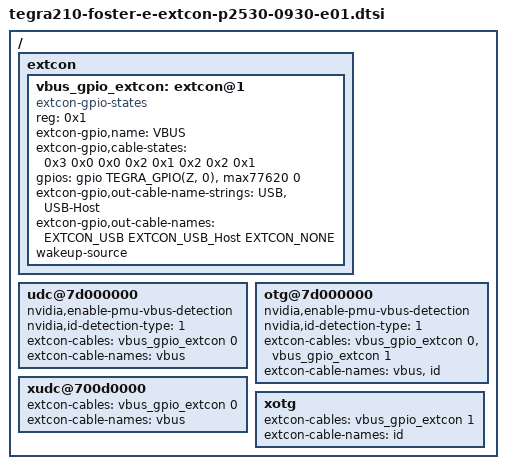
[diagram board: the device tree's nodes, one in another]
/*
 * Copyright (c) 2014-2016, NVIDIA CORPORATION.  All rights reserved.
 *
 * This program is free software; you can redistribute it and/or modify it
 * under the terms and conditions of the GNU General Public License,
 * version 2, as published by the Free Software Foundation.
 *
 * This program is distributed in the hope it will be useful, but WITHOUT
 * ANY WARRANTY; without even the implied warranty of MERCHANTABILITY or
 * FITNESS FOR A PARTICULAR PURPOSE.  See the GNU General Public License for
 * more details.
 */

#define EXTCON_NONE             0
#define EXTCON_USB              1
#define EXTCON_USB_Host         2

/ {
	extcon {
		vbus_gpio_extcon: extcon@1 {
			compatible = "extcon-gpio-states";
			reg = <0x1>;
			extcon-gpio,name = "VBUS";
			extcon-gpio,cable-states = <0x3 0x0
						    0x0 0x2
						    0x1 0x2
						    0x2 0x1>;
			gpios = <&gpio TEGRA_GPIO(Z, 0) 0 &max77620 0 0>;
			extcon-gpio,out-cable-name-strings = "USB", "USB-Host";
			extcon-gpio,out-cable-names = <EXTCON_USB EXTCON_USB_Host EXTCON_NONE>;
			wakeup-source;
			#extcon-cells = <1>;
		};
	};

	udc@7d000000 {
		nvidia,enable-pmu-vbus-detection;
		nvidia,id-detection-type = <1>;
		extcon-cables = <&vbus_gpio_extcon 0>;
		extcon-cable-names = "vbus";
	};

	otg@7d000000 {
		nvidia,enable-pmu-vbus-detection;
		nvidia,id-detection-type = <1>;
		extcon-cables = <&vbus_gpio_extcon 0 &vbus_gpio_extcon 1>;
		extcon-cable-names = "vbus", "id";
	};

	xudc@700d0000 {
		extcon-cables = <&vbus_gpio_extcon 0>;
		extcon-cable-names = "vbus";
	};

	xotg {
		extcon-cables = <&vbus_gpio_extcon 1>;
		extcon-cable-names = "id";
	};
};
